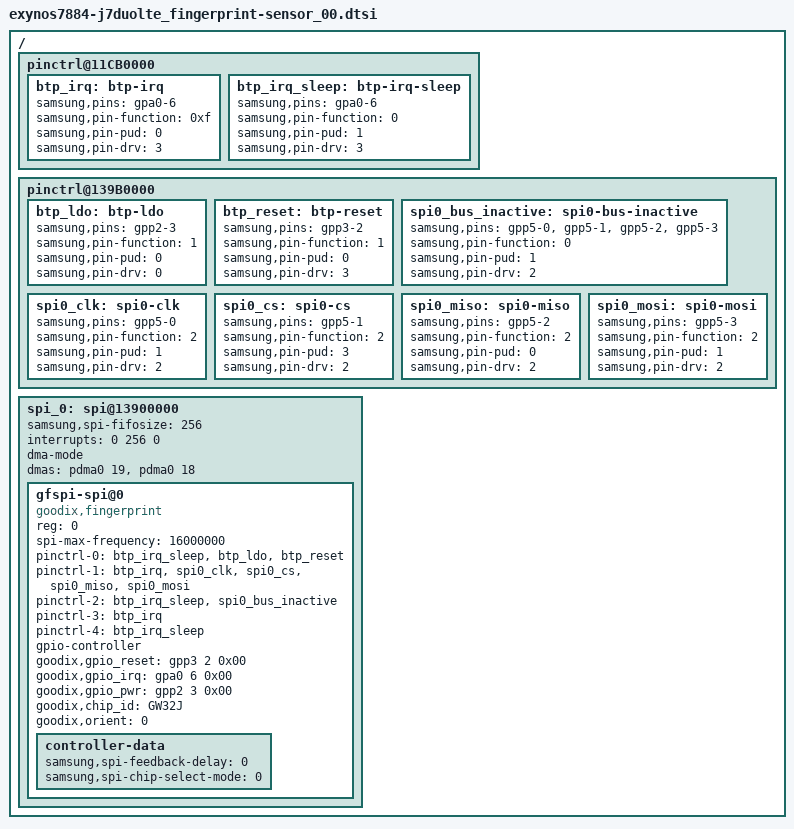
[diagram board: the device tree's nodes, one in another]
/*
 * Copyright (c) 2012-2013, The Linux Foundation. All rights reserved.
 *
 * This program is free software; you can redistribute it and/or modify
 * it under the terms of the GNU General Public License version 2 and
 * only version 2 as published by the Free Software Foundation.
 *
 * This program is distributed in the hope that it will be useful,
 * but WITHOUT ANY WARRANTY; without even the implied warranty of
 * MERCHANTABILITY or FITNESS FOR A PARTICULAR PURPOSE.  See the
 * GNU General Public License for more details.
 */

/ {
	pinctrl@11CB0000 {
		btp_irq: btp-irq {
			samsung,pins = "gpa0-6";
			samsung,pin-function = <0xf>;
			samsung,pin-pud = <0>;
			samsung,pin-drv = <3>;
		};

		btp_irq_sleep: btp-irq-sleep {
			samsung,pins = "gpa0-6";
			samsung,pin-function = <0>;
			samsung,pin-pud = <1>;
			samsung,pin-drv = <3>;
		};
	};

	pinctrl@139B0000 {
		btp_ldo: btp-ldo {
			samsung,pins = "gpp2-3";
			samsung,pin-function = <1>;
			samsung,pin-pud = <0>;
			samsung,pin-drv = <0>;
		};

		btp_reset: btp-reset {
			samsung,pins = "gpp3-2";
			samsung,pin-function = <1>;
			samsung,pin-pud = <0>;
			samsung,pin-drv = <3>;
		};
	};

	pinctrl@139B0000 {
		/* SPI_FP */
		spi0_bus_inactive: spi0-bus-inactive {
			samsung,pins = "gpp5-0", "gpp5-1", "gpp5-2", "gpp5-3";
			samsung,pin-function = <0>;
			samsung,pin-pud = <1>;
			samsung,pin-drv = <2>;
		};
		spi0_clk: spi0-clk {
			samsung,pins = "gpp5-0";
			samsung,pin-function = <2>;
			samsung,pin-pud = <1>;
			samsung,pin-drv = <2>;
		};
		spi0_cs: spi0-cs {
			samsung,pins = "gpp5-1";
			samsung,pin-function = <2>;
			samsung,pin-pud = <3>;
			samsung,pin-drv = <2>;
		};
		spi0_miso: spi0-miso {
			samsung,pins = "gpp5-2";
			samsung,pin-function = <2>;
			samsung,pin-pud = <0>;
			samsung,pin-drv = <2>;
		};
		spi0_mosi: spi0-mosi {
			samsung,pins = "gpp5-3";
			samsung,pin-function = <2>;
			samsung,pin-pud = <1>;
			samsung,pin-drv = <2>;
		};
	};

	/* spi_0 uses only for rev0.0 */
	spi_0: spi@13900000 {
		status = "okay";
		#address-cells = <1>;
		#size-cells = <0>;
		/delete-property/ pinctrl-names;
		/delete-property/ pinctrl-0;
		samsung,spi-fifosize = <256>;
		interrupts = <0 256 0>;

		dma-mode;
		dmas = <&pdma0 19
			&pdma0 18>;

		dma-names = "tx", "rx";
		gfspi-spi@0 {
			compatible = "goodix,fingerprint";
			reg = <0>;
			spi-max-frequency = <16000000>;
			pinctrl-names = "default", "pins_poweron", "pins_poweroff"
							, "pins_poweron_tz", "pins_poweroff_tz";
			pinctrl-0 = <&btp_irq_sleep &btp_ldo &btp_reset>;
			pinctrl-1 = <&btp_irq &spi0_clk &spi0_cs &spi0_miso &spi0_mosi>;
			pinctrl-2 = <&btp_irq_sleep &spi0_bus_inactive>;
			pinctrl-3 = <&btp_irq>;
			pinctrl-4 = <&btp_irq_sleep>;

			gpio-controller;
			#gpio-cells = <2>;

			goodix,gpio_reset = <&gpp3 2 0x00>;
			goodix,gpio_irq = <&gpa0 6 0x00>;
			goodix,gpio_pwr = <&gpp2 3 0x00>;
			goodix,chip_id = "GW32J";
			goodix,orient = <0>;
			controller-data {
				samsung,spi-feedback-delay = <0>;
				samsung,spi-chip-select-mode = <0>;
			};
		};
	};
};

